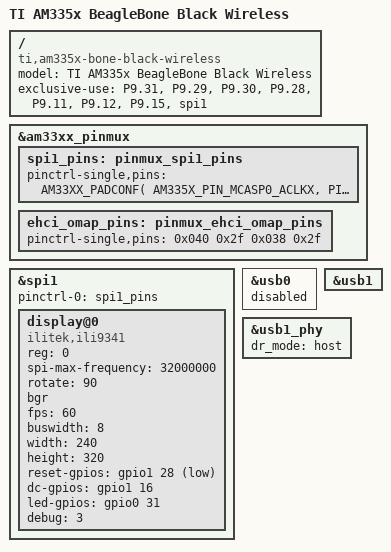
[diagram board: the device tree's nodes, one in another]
/dts-v1/;

#include "am33xx.dtsi"
#include "am335x-bone-common.dtsi"
#include "am335x-boneblack-common.dtsi"
#include <dt-bindings/interrupt-controller/irq.h>
/ {
    model = "TI AM335x BeagleBone Black Wireless";
    compatible = "ti,am335x-bone-black-wireless", "ti,am335x-bone-black", "ti,am335x-bone", "ti,am33xx";
      exclusive-use =
        /* the pin header uses */
       "P9.31", /* spi1_sclk */
       "P9.29", /* spi1_d0 MISO */
       "P9.30", /* spi1_d1 MOSI */
       "P9.28", /* spi1_cs0 */
       "P9.11", /* gpio0_30 - reset */
       "P9.12", /* gpio1_28 - dc */
       "P9.15", /* gpio1_16 - led */
       "spi1";
};

&am33xx_pinmux {
  spi1_pins: pinmux_spi1_pins{
    pinctrl-single,pins = <
      AM33XX_PADCONF( AM335X_PIN_MCASP0_ACLKX,  PIN_INPUT_PULLUP, MUX_MODE3 )  // P9_31: spi1 clk out
      AM33XX_PADCONF( AM335X_PIN_MCASP0_FSX,    PIN_INPUT_PULLDOWN, MUX_MODE3 )  // P9_29: spi1 d0 /data in (miso)
      AM33XX_PADCONF( AM335X_PIN_MCASP0_AXR0,   PIN_OUTPUT_PULLDOWN, MUX_MODE3 )  // P9_30: spi1 d1 / data out (mosi)
      AM33XX_PADCONF( AM335X_PIN_MCASP0_AHCLKR, PIN_OUTPUT_PULLDOWN, MUX_MODE3 )  // P9_28: spi1 cs 0 out
    >;
  };
   ehci_omap_pins: pinmux_ehci_omap_pins {
                pinctrl-single,pins = <
                    /* configure pins for USB1 */
                    0x040 0x2f  /* gpmc_wait0, EHCI0 reset */
                    0x038 0x2f  /* gpmc_advn_ale, EHCI0 vbus */
                >;
            }; 
};

&spi1 {
  status="okay";
  pinctrl-names = "default";
  pinctrl-0 = <&spi1_pins>;
  #address-cells = <1>;
  #size-cells = <0>;
  };

&spi1{
    display@0 {
      compatible = "ilitek,ili9341";
      reg = <0>;
      pinctrl-names = "default";
      spi-max-frequency = <32000000>;
      rotate = <90>;
      bgr;
      fps = <60>;
      buswidth = <8>;
      width = <240>;
      height = <320>;
      reset-gpios = <&gpio1 28 GPIO_ACTIVE_LOW>;
      dc-gpios = <&gpio1 16 GPIO_ACTIVE_HIGH>;
      led-gpios= <&gpio0 31 0>;
      debug = <3>;
      };
  };


&usb0{
    status = "disabled";
};

&usb0{
    status = "disabled";
};

&usb1{
    status = "okay";
};

&usb1_phy{
    dr_mode = "host";
    status = "okay";
};

